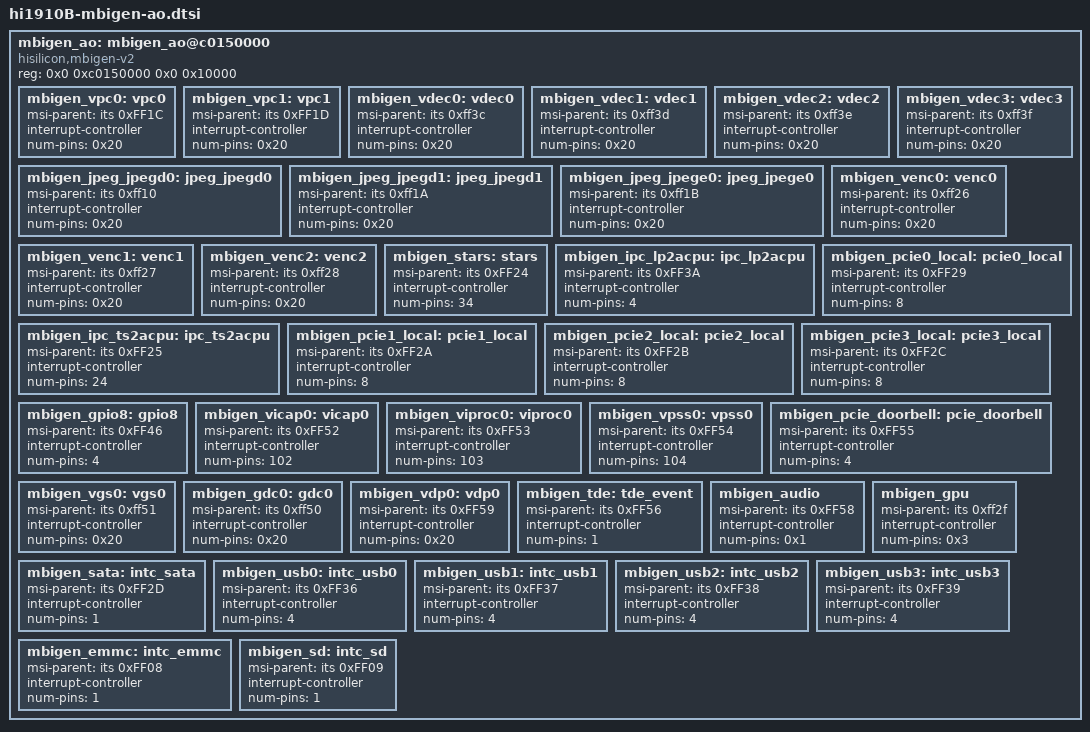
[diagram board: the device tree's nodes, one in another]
/**
* dts file for Hisilicon Ascend Dxxx Development Board
*
* Copyright (C) 2020 Hisilicon Ltd.
*
* This program is free software; you can redistribute it and/or modify
* it under the terms of the GNU General Public License version 2 as
* publishhed by the Free Software Foundation.
*
* Owner：OS
* Author:  c00283067
* Create: Tue Apr 21 20:07:41 EDT 2020
*/
    mbigen_ao: mbigen_ao@c0150000 {
        compatible = "hisilicon,mbigen-v2";
        reg = <0x0 0xc0150000 0x0 0x10000>;

        mbigen_vpc0: vpc0 {
            msi-parent = <&its 0xFF1C>; // device num: 0x1C
            interrupt-controller;
            #interrupt-cells = <0x2>;
            num-pins = <0x20>;
        };

        mbigen_vpc1: vpc1 {
            msi-parent = <&its 0xFF1D>; // device num: 0x1D
            interrupt-controller;
            #interrupt-cells = <0x2>;
            num-pins = <0x20>;
        };

	mbigen_vdec0: vdec0 {
		msi-parent = <&its 0xff3c>;
		interrupt-controller;
		#interrupt-cells = <0x2>;
		num-pins = <0x20>;
	};

	mbigen_vdec1: vdec1 {
		msi-parent = <&its 0xff3d>;
		interrupt-controller;
		#interrupt-cells = <0x2>;
		num-pins = <0x20>;
	};

	mbigen_vdec2: vdec2 {
		msi-parent = <&its 0xff3e>;
		interrupt-controller;
		#interrupt-cells = <0x2>;
		num-pins = <0x20>;
	};

	mbigen_vdec3: vdec3 {
		msi-parent = <&its 0xff3f>;
		interrupt-controller;
		#interrupt-cells = <0x2>;
		num-pins = <0x20>;
	};

	mbigen_jpeg_jpegd0: jpeg_jpegd0 {
		msi-parent = <&its 0xff10>;
		interrupt-controller;
		#interrupt-cells = <0x2>;
		num-pins = <0x20>;
	};

	mbigen_jpeg_jpegd1: jpeg_jpegd1 {
		msi-parent = <&its 0xff1A>;
		interrupt-controller;
		#interrupt-cells = <0x2>;
		num-pins = <0x20>;
	};

	mbigen_jpeg_jpege0: jpeg_jpege0 {
		msi-parent = <&its 0xff1B>;
		interrupt-controller;
		#interrupt-cells = <0x2>;
		num-pins = <0x20>;
	};

	mbigen_venc0: venc0 {
		msi-parent = <&its 0xff26>;
		interrupt-controller;
		#interrupt-cells = <0x2>;
		num-pins = <0x20>;
	};

	mbigen_venc1: venc1 {
		msi-parent = <&its 0xff27>;
		interrupt-controller;
		#interrupt-cells = <0x2>;
		num-pins = <0x20>;
	};

	mbigen_venc2: venc2 {
		msi-parent = <&its 0xff28>;
		interrupt-controller;
		#interrupt-cells = <0x2>;
		num-pins = <0x20>;
	};

        mbigen_stars: stars {
            msi-parent = <&its 0xFF24>; // device num: 0x1D
            interrupt-controller;
            #interrupt-cells = <0x2>;
            num-pins = <34>;
        };

        mbigen_ipc_lp2acpu: ipc_lp2acpu {
           msi-parent = <&its 0xFF3A>; // device num: 0x3A
           interrupt-controller;
           #interrupt-cells = <0x2>;
           num-pins = <4>;
        };

        mbigen_ipc_ts2acpu: ipc_ts2acpu {
            msi-parent = <&its 0xFF25>; // device num: 0x25
            interrupt-controller;
            #interrupt-cells = <0x2>;
            num-pins = <24>;
        };

        mbigen_pcie0_local: pcie0_local {
            msi-parent = <&its 0xFF29>; // device num: 0x29
            interrupt-controller;
            #interrupt-cells = <0x2>;
            num-pins = <8>;
        };

        mbigen_pcie1_local: pcie1_local {
            msi-parent = <&its 0xFF2A>; // device num: 0x2A
            interrupt-controller;
            #interrupt-cells = <0x2>;
            num-pins = <8>;
        };

        mbigen_pcie2_local: pcie2_local {
            msi-parent = <&its 0xFF2B>; // device num: 0x2B
            interrupt-controller;
            #interrupt-cells = <0x2>;
            num-pins = <8>;
        };

        mbigen_pcie3_local: pcie3_local {
            msi-parent = <&its 0xFF2C>; // device num: 0x2C
            interrupt-controller;
            #interrupt-cells = <0x2>;
            num-pins = <8>;
        };

        mbigen_gpio8: gpio8 {
            msi-parent = <&its 0xFF46>; // device num: 0x46
            interrupt-controller;
            #interrupt-cells = <0x2>;
            num-pins = <4>;
        };

        mbigen_vicap0: vicap0 {
            msi-parent = <&its 0xFF52>; // device num: 0x52
            interrupt-controller;
            #interrupt-cells = <0x2>;
            num-pins = <102>;
        };
        mbigen_viproc0: viproc0 {
            msi-parent = <&its 0xFF53>; // device num: 0x53
            interrupt-controller;
            #interrupt-cells = <0x2>;
            num-pins = <103>;
        };
        mbigen_vpss0: vpss0 {
            msi-parent = <&its 0xFF54>; // device num: 0x54
            interrupt-controller;
            #interrupt-cells = <0x2>;
            num-pins = <104>;
        };

        mbigen_pcie_doorbell: pcie_doorbell {
            msi-parent = <&its 0xFF55>; // device num: 0x55
            interrupt-controller;
            #interrupt-cells = <0x2>;
            num-pins = <4>;
        };
	mbigen_vgs0: vgs0 {
        	msi-parent = <&its 0xff51>;
        	interrupt-controller;
        	#interrupt-cells = <0x2>;
        	num-pins = <0x20>;
        };
        mbigen_gdc0: gdc0 {
        	msi-parent = <&its 0xff50>;
        	interrupt-controller;
        	#interrupt-cells = <0x2>;
        	num-pins = <0x20>;
        };
	mbigen_vdp0: vdp0 {
		msi-parent = <&its 0xFF59>; // device num: 0x59
		interrupt-controller;
		#interrupt-cells = <0x2>;
		num-pins = <0x20>;
	};
	mbigen_tde: tde_event {
		msi-parent = <&its 0xFF56>;
		interrupt-controller;
		#interrupt-cells = <0x2>;
		num-pins = <1>;
	};
	mbigen_audio: mbigen_audio {
		msi-parent = <&its 0xFF58>;
		interrupt-controller;
		#interrupt-cells = <0x2>;
		num-pins = <0x1>;
	};
	mbigen_gpu: mbigen_gpu {
		msi-parent = <&its 0xff2f>;
		interrupt-controller;
		#interrupt-cells = <0x2>;
		num-pins = <0x3>;
	};
	mbigen_sata:intc_sata {
		msi-parent = <&its 0xFF2D>;
		interrupt-controller;
		#interrupt-cells = <2>;
		num-pins = <1>;
	};
	mbigen_usb0:intc_usb0 {
		msi-parent = <&its 0xFF36>;
		interrupt-controller;
		#interrupt-cells = <2>;
		num-pins = <4>;
	};
	mbigen_usb1:intc_usb1 {
		msi-parent = <&its 0xFF37>;
		interrupt-controller;
		#interrupt-cells = <2>;
		num-pins = <4>;
	};

    mbigen_usb2: intc_usb2 {
        msi-parent = <&its 0xFF38>;
        interrupt-controller;
        #interrupt-cells = <0x2>;
        num-pins = <4>;
    };

    mbigen_usb3: intc_usb3  {
        msi-parent = <&its 0xFF39>;
        interrupt-controller;
        #interrupt-cells = <0x2>;
        num-pins = <4>;
    };

	mbigen_emmc:intc_emmc {
		msi-parent = <&its 0xFF08>;
		interrupt-controller;
		#interrupt-cells = <2>;
		num-pins = <1>;
	};
	mbigen_sd:intc_sd {
		msi-parent = <&its 0xFF09>;
		interrupt-controller;
		#interrupt-cells = <2>;
		num-pins = <1>;
	};
    };
